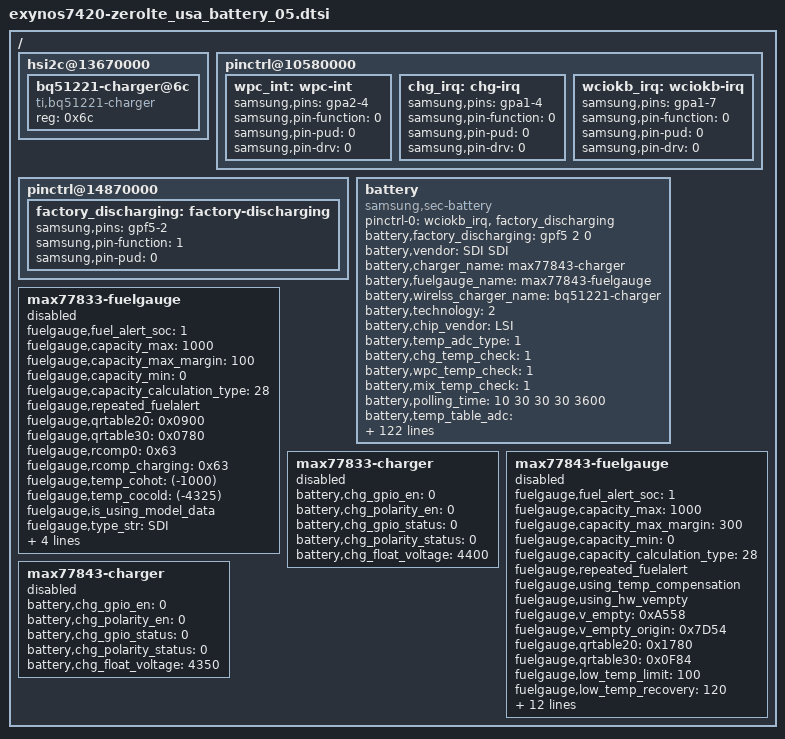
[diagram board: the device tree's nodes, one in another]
/*
 * SAMSUNG UNIVERSAL5433 board device tree source
 *
 * Copyright (c) 2013 Samsung Electronics Co., Ltd.
 *		http://www.samsung.com
 *
 * This program is free software; you can redistribute it and/or modify
 * it under the terms of the GNU General Public License version 2 as
 * published by the Free Software Foundation.
*/

/ {
	hsi2c@13670000 { /* hsi2c5 */
		status = "okay";

		bq51221-charger@6c {
			compatible = "ti,bq51221-charger";
			reg = <0x6c>;
			status = "okay";
		};
	};

	pinctrl@10580000 {
		wpc_int: wpc-int {
			samsung,pins = "gpa2-4";
			samsung,pin-function = <0>;
			samsung,pin-pud = <0>;
			samsung,pin-drv = <0>;
		};
		chg_irq: chg-irq {
			 samsung,pins = "gpa1-4";
			 samsung,pin-function = <0>;
			 samsung,pin-pud = <0>;
			 samsung,pin-drv = <0>;
		};

		wciokb_irq: wciokb-irq {
			 samsung,pins = "gpa1-7";
			 samsung,pin-function = <0>;
			 samsung,pin-pud = <0>;
			 samsung,pin-drv = <0>;
		};

	};

	pinctrl@14870000 {
		factory_discharging: factory-discharging {
			samsung,pins = "gpf5-2";
			samsung,pin-function = <1>;
			samsung,pin-pud = <0>;
		};
	};

	battery {
		status = "okay";

		pinctrl-names = "default";
		pinctrl-0 = <&wciokb_irq &factory_discharging>;

		battery,factory_discharging = <&gpf5 2 0>;

		compatible = "samsung,sec-battery";
		battery,vendor = "SDI SDI";
		battery,charger_name = "max77843-charger";
		battery,fuelgauge_name = "max77843-fuelgauge";
		battery,wirelss_charger_name = "bq51221-charger";
		battery,technology = <2>; /* POWER_SUPPLY_TECHNOLOGY_LION */
		/* .temp_cohot = -1000; */
		/* .temp_cocold = -4325; */

		battery,chip_vendor = "LSI";
		battery,temp_adc_type = <1>; /* SEC_BATTERY_ADC_TYPE_AP */

		battery,chg_temp_check = <1>;
		battery,wpc_temp_check = <1>;
		battery,mix_temp_check = <1>;

		battery,polling_time = <10 30 30 30 3600>;

		battery,temp_table_adc = <280 326 383 429 489 559 631 727 807 925
					1015 1114 1217 1341 1448 1545 1625
					  1712 1778 1830 1873 1914 1937>;
		battery,temp_table_data = <900 850 800 750 700 650 600 550 500 450
					   400 350 300 250 200 150 100
					   50 0 (-50) (-100) (-150) (-200)>;

		battery,chg_temp_table_adc = <499 538 598 717 835 1026 1124
					      1240 1478 1568 1834 2023 2189 2429
					      2631 2851 2948 3053 3239 3325>;
		battery,chg_temp_table_data = <750 700 650 600 550 500 450
					       400 350 300 250 200 150 100
					       50 0 (-50) (-100) (-150) (-200)>;

		battery,input_current_limit = <1800 0 0 1800 460 900 1000 460 1000 0 820 820 820 1900 1800 0 0 400 700 1300 300 1000 1500 0 1667 1000 1667 80 1800 1667 1400 1000 1000 1800>;
		battery,fast_charging_current = <2050 0 0 2050 460 1200 1000 460 1200 0 1150 1150 1150 1600 2050 0 0 400 700 1300 300 1000 1500 0 2050 1000 2050 80 1800 1000 1400 0 1000 2050>;
		battery,full_check_current_1st = <275 0 0 275 275 275 275 275 275 0 275 275 275 275 275 0 0 275 275 275 275 275 275 0 275 275 275 0 275 275 275 0 275 275>;
		battery,full_check_current_2nd = <125 0 0 125 125 125 125 125 125 0 125 125 125 125 125 0 0 125 125 125 125 125 125 0 125 125 125 0 125 125 125 0 125 125>;

		battery,wireless_cc_cv = <90>;
		battery,inbat_voltage = <1>;

		battery,inbat_voltage_table_adc = <3137 3113 3077 3045 3010 2976 2942 2904 2874 2832
						2794 2763 2723 2693 2660 2623 2589 2552 2517 2481 2464>;
		battery,inbat_voltage_table_data = <438 435 430 425 420 415 410 405 400 395
						390 385 380 375 370 365 360 355 350 345 340>;

		battery,adc_check_count = <5>;

		battery,cable_check_type = <4>; /* SEC_BATTERY_CABLE_CHECK_PSY */
		battery,cable_source_type = <1>; /* SEC_BATTERY_CABLE_SOURCE_EXTERNAL */
		battery,event_waiting_time = <600>;
		battery,polling_type = <1>; /* SEC_BATTERY_MONITOR_ALARM */
		battery,monitor_initial_count = <0>;

		battery,battery_check_type = <0>;
		battery,check_count = <0>;
		battery,check_adc_max = <1440>;
		battery,check_adc_min = <0>;

		battery,ovp_uvlo_check_type = <3>; /* SEC_BATTERY_OVP_UVLO_CHGPOLLING */

		battery,thermal_source = <2>; /* SEC_BATTERY_THERMAL_SOURCE_ADC */

		battery,temp_check_type = <2>; /* _BATTERY_TEMP_CHECK_TEMP */
		battery,temp_check_count = <1>;
		battery,temp_highlimit_threshold_event = <800>;
		battery,temp_highlimit_recovery_event = <750>;
		battery,temp_high_threshold_event = <500>;
		battery,temp_high_recovery_event = <450>;
		battery,temp_low_threshold_event = <0>;
		battery,temp_low_recovery_event = <50>;
		battery,temp_highlimit_threshold_normal = <800>;
		battery,temp_highlimit_recovery_normal = <750>;
		battery,temp_high_threshold_normal = <500>;
		battery,temp_high_recovery_normal = <450>;
		battery,temp_low_threshold_normal = <0>;
		battery,temp_low_recovery_normal = <50>;
		battery,temp_highlimit_threshold_lpm = <800>;
		battery,temp_highlimit_recovery_lpm = <750>;
		battery,temp_high_threshold_lpm = <500>;
		battery,temp_high_recovery_lpm = <450>;
		battery,temp_low_threshold_lpm = <0>;
		battery,temp_low_recovery_lpm = <50>;
		battery,wpc_high_threshold_normal = <450>;
		battery,wpc_high_recovery_normal = <400>;
		battery,wpc_low_threshold_normal = <0>;
		battery,wpc_low_recovery_normal = <50>;		
		battery,full_check_type = <7>; /* SEC_BATTERY_FULLCHARGED_CHGPSY */
		battery,full_check_type_2nd = <7>; /* SEC_BATTERY_FULLCHARGED_CHGPSY */
		battery,full_check_count = <1>;
		battery,chg_gpio_full_check = <0>;
		battery,chg_polarity_full_check = <1>;

		battery,chg_high_temp_1st = <580>;
		battery,chg_high_temp_2nd = <580>;
		battery,chg_high_temp_recovery = <200>;
		battery,chg_charging_limit_current = <1300>;
		battery,chg_charging_limit_current_2nd = <1300>;
		battery,chg_skip_check_capacity = <10>;
		battery,chg_skip_check_time = <600>;

		battery,wpc_high_temp = <380>;
		battery,wpc_high_temp_recovery = <370>;
		battery,wpc_charging_limit_current = <450>;

		battery,wpc_delayed_current_en;
		battery,wpc_delayed_current = <860>;
		battery,wpc_delayed_current_time = <420>;

		battery,mix_high_tbat = <990>;
		battery,mix_high_tchg = <990>;
		battery,mix_high_tbat_recov = <330>;
		battery,mix_input_limit_current = <100>;
		battery,mix_high_tbat_hv = <400>;
		battery,mix_high_tchg_hv = <500>;
		battery,mix_high_tbat_recov_hv = <370>;
		battery,mix_input_limit_current_hv = <100>;

		/* SEC_BATTERY_FULL_CONDITION_SOC |
		   SEC_BATTERY_FULL_CONDITION_NOTIMEFULL |
		   SEC_BATTERY_FULL_CONDITION_VCELL */
		battery,full_condition_type = <13>;
		battery,full_condition_soc = <93>;
		battery,full_condition_vcell = <4250>;

		battery,recharge_check_count = <2>;
		battery,recharge_condition_type = <4>; /* SEC_BATTERY_RECHARGE_CONDITION_VCELL */
		battery,recharge_condition_soc = <98>;
		battery,recharge_condition_vcell = <4300>;

		battery,charging_total_time = <14400>;
		battery,hv_charging_total_time = <10800>;
		battery,normal_charging_total_time = <18000>;
		battery,usb_charging_total_time = <36000>;
		battery,recharging_total_time = <5400>;
		battery,charging_reset_time = <0>;

		battery,chg_float_voltage = <4350>;

		battery,self_discharging_en;
		battery,force_discharging_limit = <650>;
		battery,force_discharging_recov = <550>;
		battery,self_discharging_voltage_limit = <4250>;
		battery,discharging_adc_max = <2600>;
		battery,discharging_adc_min = <1700>;
		battery,discharging_ntc_limit = <2750>;

		battery,swelling_high_temp_block = <410>;
		battery,swelling_high_temp_recov = <360>;
		battery,swelling_low_temp_block = <100>;
		battery,swelling_low_temp_recov = <150>;
		battery,swelling_chg_current = <1150>;
		battery,swelling_drop_float_voltage = <4150>;
		battery,swelling_high_rechg_voltage = <4100>;
		battery,swelling_low_rechg_voltage = <4000>;
		battery,swelling_block_time = <600>;
		battery,swelling_wc_chg_current = <750>;	/* 0.8C * 0.3C */

		/* cycle, chg_float_voltage, recharge_condition_vcell, full_condition_vcell, full_condition_soc */
		battery,age_data = <0 4350 4300 4250 93
				200 4330 4280 4230 89
				250 4310 4260 4210 85
				300 4290 4240 4190 80
				1000 4240 4190 4140 75>;

		io-channels = <&exynos_adc 1>, <&exynos_adc 3>, <&exynos_adc 6>, <&exynos_adc 5>, <&exynos_adc 7>;
		io-channel-names = "adc-temp", "chg-adc-temp", "in-bat-adc", "discharging-check-adc", "ntc-check-adc";
		#io-channel-cells = <5>;
		io-channel-ranges;

		battery,cisd_cap_high_thr = <3600>;
		battery,cisd_cap_low_thr = <3100>;
		battery,cisd_cap_limit = <2860>;
	};

	max77833-fuelgauge {
		status = "disable";
		fuelgauge,fuel_alert_soc = <1>;
		fuelgauge,capacity_max = <1000>;
		fuelgauge,capacity_max_margin = <100>;
		fuelgauge,capacity_min = <0>;
		fuelgauge,capacity_calculation_type = <28>;
		fuelgauge,repeated_fuelalert;
		fuelgauge,qrtable20 = <0x0900>;
		fuelgauge,qrtable30 = <0x0780>;
		fuelgauge,rcomp0 = <0x63>;
		fuelgauge,rcomp_charging = <0x63>;
		fuelgauge,temp_cohot = <(-1000)>;
		fuelgauge,temp_cocold = <(-4325)>;
		fuelgauge,is_using_model_data;
		fuelgauge,type_str = "SDI";
		fuelgauge,capacity = <0x19C8>;
		fuelgauge,low_battery_comp_voltage = <3600>;
		fuelgauge,low_battery_table = <(-5000) 0 0 (-1250) 0 3320 (-750) 97 3451 (-100) 96 3461 0 0 3456>;
	};
	max77833-charger {
	        status = "disable";
		battery,chg_gpio_en = <0>;
		battery,chg_polarity_en = <0>;
		battery,chg_gpio_status = <0>;
		battery,chg_polarity_status = <0>;
		battery,chg_float_voltage = <4400>;
	};

	max77843-fuelgauge {
		status = "disable";
		fuelgauge,fuel_alert_soc = <1>;
		fuelgauge,capacity_max = <1000>;
		fuelgauge,capacity_max_margin = <300>;
		fuelgauge,capacity_min = <0>;
		fuelgauge,capacity_calculation_type = <28>;
		fuelgauge,repeated_fuelalert;
		fuelgauge,using_temp_compensation;
		fuelgauge,using_hw_vempty;
		fuelgauge,v_empty = <0xA558>;
		fuelgauge,v_empty_origin = <0x7D54>;
		fuelgauge,qrtable20 = <0x1780>;
		fuelgauge,qrtable30 = <0x0F84>;
		fuelgauge,low_temp_limit = <100>;
		fuelgauge,low_temp_recovery = <120>;
		fuelgauge,temp_cohot = <0x2332>;
		fuelgauge,temp_cocold = <0x2332>;
		fuelgauge,rcomp0 = <0x3C>;
		fuelgauge,rcomp_charging = <0x3C>;
		fuelgauge,is_using_model_data;
		fuelgauge,type_str = "SDI";
		fuelgauge,capacity = <0x14C2>;
		fuelgauge,low_battery_comp_voltage = <3600>;
		fuelgauge,low_battery_table = <(-5000) 0 0 (-1250) 0 3320 (-750) 97 3451 (-100) 96 3461 0 0 3456>;
		fuelgauge,cv_data = <2565  680    2580
			2483  688    2549
			2405  696    2519
			2333  704    2489
			2263  711    2458
			2196  718    2428
			2137  725    2398
			2077  732    2367
			2016  738    2337
			1964  745    2306
			1894  751    2276
			1835  757    2246
			1783  763    2215
			1727  769    2185
			1674  774    2155
			1621  780    2124
			1571  785    2094
			1525  790    2064
			1480  795    2033
			1437  800    2003
			1391  804    1973
			1353  809    1942
			1311  814    1912
			1272  818    1882
			1235  822    1851
			1198  826    1821
			1161  830    1791
			1124  834    1760
			1092  838    1730
			1059  841    1700
			1027  845    1669
			996   848    1639
			969   852    1608
			940   855    1578
			909   858    1548
			885   861    1517
			863   864    1487
			840   867    1457
			817   870    1426
			794   872    1396
			771   875    1366
			749   878    1335
			725   880    1305
			707   883    1275
			696   885    1244
			674   887    1214
			658   890    1184
			640   892    1153
			618   894    1123
			608   896    1093
			604   898    1062
			584   900    1032
			567   903    1002
			553   909    971
			539   913    941
			524   918    910
			515   921    880
			507   924    850
			494   929    820
			476   934    789
			469   937    759
			459   939    729
			449   943    698
			438   946    668
			431   949    638
			419   952    607
			408   957    577
			402   958    546
			389   962    516
			385   964    486
			377   966    455
			371   968    425
			359   972    395
			353   975    364
			347   976    334
			337   979    304
			331   981    273
			327   983    243
			323   985    213
			319   986    182
			306   989    152
			303   992    122
			298   993    91
			293   996    61
			290   997    31
			0     1000   0 >;
	};

	max77843-charger {
	        status = "disable";
		battery,chg_gpio_en = <0>;
		battery,chg_polarity_en = <0>;
		battery,chg_gpio_status = <0>;
		battery,chg_polarity_status = <0>;
		battery,chg_float_voltage = <4350>;
	};
};
